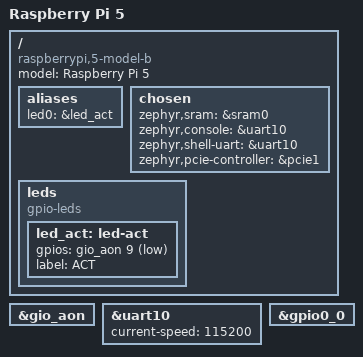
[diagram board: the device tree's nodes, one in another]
/*
 * Copyright 2024 Junho Lee <junho@tsnlab.com>
 *
 * SPDX-License-Identifier: Apache-2.0
 */

/dts-v1/;

#include <broadcom/bcm2712.dtsi>
#include <zephyr/dt-bindings/gpio/gpio.h>

/ {
	compatible = "raspberrypi,5-model-b", "brcm,bcm2712";
	model = "Raspberry Pi 5";
	#address-cells = <2>;
	#size-cells = <1>;

	aliases {
		led0 = &led_act;
	};

	chosen {
		zephyr,sram = &sram0;
		zephyr,console = &uart10;
		zephyr,shell-uart = &uart10;
		zephyr,pcie-controller = &pcie1;
	};

	leds {
		compatible = "gpio-leds";

		led_act: led-act {
			gpios = <&gio_aon 9 GPIO_ACTIVE_LOW>;
			label = "ACT";
		};
	};
};

&gio_aon {
	status = "okay";
};

&uart10 {
	status = "okay";
	current-speed = <115200>;
};

&gpio0_0 {
	status = "okay";
};
